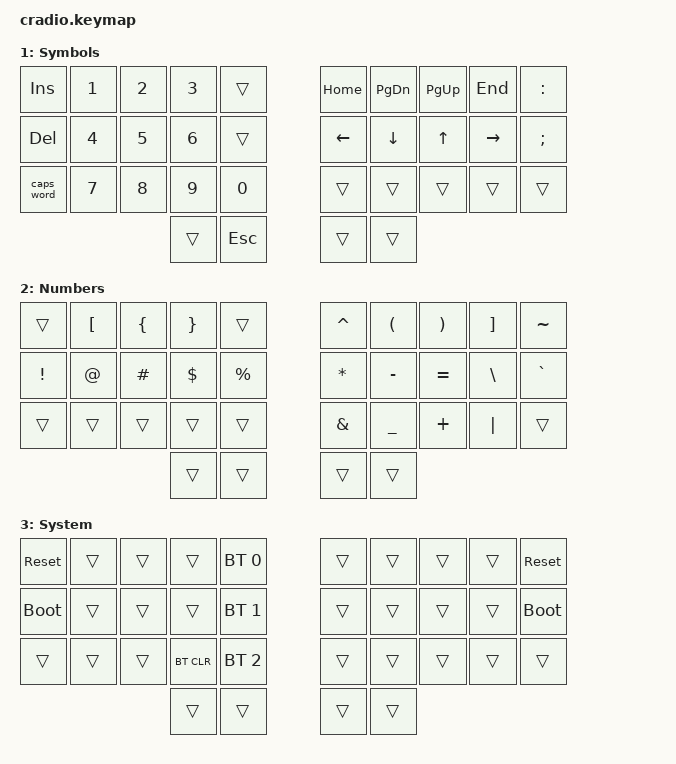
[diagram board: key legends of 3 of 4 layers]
// Copyright (c) 2022 The ZMK Contributors
// SPDX-License-Identifier: MIT

#include <behaviors.dtsi>
#include <dt-bindings/zmk/keys.h>
#include <dt-bindings/zmk/bt.h>

#define KEYS_L 0 1 2 3 4 10 11 12 13 14 20 21 22 23 24
#define KEYS_R 5 6 7 8 9 15 16 17 18 19 25 26 27 28 29

#define HRMR(k1,k2,k3,k4) \
    &hmr RGUI k1 \
    &hmr RCTRL k2 \
    &hmr RALT k3 \
    &hmr RSHFT k4

/ {
	behaviors {
		hml: left_homerow_mods {
			compatible = "zmk,behavior-hold-tap";
			#binding-cells = <2>;
			flavor = "balanced";
			tapping-term-ms = <150>; // <--- DECREASE THIS VALUE
			quick-tap-ms = <175>;
			bindings = <&kp>, <&kp>;
			hold-trigger-key-positions = <KEYS_R>;
			hold-trigger-on-release;
		};

		hmr: right_homerow_mods {
			compatible = "zmk,behavior-hold-tap";
			#binding-cells = <2>;
			flavor = "balanced";
			tapping-term-ms = <150>; // <--- DECREASE THIS VALUE
			quick-tap-ms = <175>;
			bindings = <&kp>, <&kp>;
			hold-trigger-key-positions = <KEYS_L>;
			hold-trigger-on-release;
		};

		lt_fast: layer_tap_fast {
			compatible = "zmk,behavior-hold-tap";
			#binding-cells = <2>;
			flavor = "hold-preferred";
			tapping-term-ms = <150>;
			quick-tap-ms = <0>;
			bindings = <&mo>, <&kp>;
		};

		td_z: tap_dance_z_esc_enter {
			compatible = "zmk,behavior-tap-dance";
			#binding-cells = <0>;
			tapping-term-ms = <200>;
			bindings = <&kp Z>, <&kp ESC>, <&kp ENTER>;
		};
	};

	keymap {
		compatible = "zmk,keymap";

	default_layer {
			display-name = "Default";
			bindings = <
        //╭──────────┬──────────┬──────────┬──────────┬──────────╮   ╭──────────┬──────────┬──────────┬──────────┬──────────╮
        //│  Q       │  W       │  E       │  R       │  T       │   │  Y       │  U       │  I       │  O       │  P       │
            &kp Q      &kp W      &kp E      &kp R      &kp T          &kp Y      &kp U      &kp I      &kp O      &kp P
        //├──────────┼──────────┼──────────┼──────────┼──────────┤   ├──────────┼──────────┼──────────┼──────────┼──────────┤
        //│  A       │  S       │  D       │  F       │  G       │   │  H       │  J       │  K       │  L       │ ' "      │
            &hml LSHFT A &kp S &kp D &hml LGUI F &kp G          &kp H      HRMR(J,     K,          L,          SEMI)
        //├──────────┼──────────┼──────────┼──────────┼──────────┤   ├──────────┼──────────┼──────────┼──────────┼──────────┤
        //│  Z       │  X       │  C       │  V       │  B       │   │  N       │  M       │ , <      │ . >      │ / ?      │
            &td_z      &kp X      &kp C      &kp V      &kp B          &kp N      &kp M      &kp COMMA  &kp DOT    &kp FSLH
        //╰──────────┴──────────┴──────────┼──────────┼──────────┤   ├──────────┼──────────┼──────────┴──────────┴──────────╯
                                            &lt_fast 2 TAB   &kp BSPC     &kp SPACE  &lt_fast 1 LS(ENTER)
        //                                 ╰──────────┴──────────╯   ╰──────────┴──────────╯
            >;
		};

right_layer {
			display-name = "Symbols";
			bindings = <
        //╭──────────┬──────────┬──────────┬──────────┬──────────╮   ╭──────────┬──────────┬──────────┬──────────┬──────────╮
        //│ INSERT   │  1       │  2       │  3       │          │   │ HOME     │ PAGE DN  │ PAGE UP  │ END      │  :       │
            &kp INS    &kp N1     &kp N2     &kp N3     &trans         &kp HOME   &kp PG_DN  &kp PG_UP  &kp END    &kp COLON
        //├──────────┼──────────┼──────────┼──────────┼──────────┤   ├──────────┼──────────┼──────────┼──────────┼──────────┤
        //│ DELETE   │  4       │  5       │  6       │          │   │ LEFT     │ DOWN     │ UP       │ RIGHT    │  ;       │
            &kp DEL    &kp N4     &kp N5     &kp N6     &trans         &kp LEFT   &kp DOWN   &kp UP   &kp RIGHT   &kp SEMI
        //├──────────┼──────────┼──────────┼──────────┼──────────┤   ├──────────┼──────────┼──────────┼──────────┼──────────┤
        //│ CAPS     │  7       │  8       │  9       │  0       │   │          │          │          │          │          │
           &caps_word  &kp N7     &kp N8     &kp N9     &kp N0         &trans     &trans     &trans     &trans     &trans
        //╰──────────┴──────────┴──────────┼──────────┼──────────┤   ├──────────┼──────────┼──────────┴──────────┴──────────╯
                                             &trans     &kp ESC        &trans     &trans
        //                                 ╰──────────┴──────────╯   ╰──────────┴──────────╯
            >;
		};

left_layer {
			display-name = "Numbers";
			bindings = <
        //╭──────────┬──────────┬──────────┬──────────┬──────────╮   ╭──────────┬──────────┬──────────┬──────────┬──────────╮
        //│          │  [       │  {       │  }       │          │   │  ^       │  (       │  )       │  ]       │  ~       │
            &trans     &kp LBKT   &kp LBRC   &kp RBRC   &trans         &kp CARET  &kp LPAR   &kp RPAR   &kp RBKT   &kp TILDE
        //├──────────┼──────────┼──────────┼──────────┼──────────┤   ├──────────┼──────────┼──────────┼──────────┼──────────┤
        //│  !       │  @       │  #       │  $       │  %       │   │  *       │  -       │  =       │  \       │  `       │
            &kp EXCL   &kp AT     &kp HASH   &kp DLLR   &kp PRCNT      &kp ASTRK  &kp MINUS  &kp EQUAL  &kp BSLH   &kp GRAVE
        //├──────────┼──────────┼──────────┼──────────┼──────────┤   ├──────────┼──────────┼──────────┼──────────┼──────────┤
        //│          │          │          │          │          │   │  &       │  _       │  +       │  │       │          │
            &trans     &trans     &trans     &trans     &trans         &kp AMPS   &kp UNDER  &kp PLUS   &kp PIPE   &trans
        //╰──────────┴──────────┴──────────┼──────────┼──────────┤   ├──────────┼──────────┼──────────┴──────────┴──────────╯
                                             &trans     &trans         &trans     &trans
        //                                 ╰──────────┴──────────╯   ╰──────────┴──────────╯
            >;
		};

tri_layer {
			display-name = "System";
			bindings = <
        //╭──────────┬──────────┬──────────┬──────────┬──────────╮   ╭──────────┬──────────┬──────────┬──────────┬──────────╮
        //│ RESET    │          │          │          │PROFILE 0 │   │          │          │          │          │  RESET   │
           &sys_reset  &trans     &trans     &trans    &bt BT_SEL 0    &trans     &trans     &trans     &trans    &sys_reset
        //├──────────┼──────────┼──────────┼──────────┼──────────┤   ├──────────┼──────────┼──────────┼──────────┼──────────┤
        //│BOOTLOADER│          │          │          │PROFILE 1 │   │          │          │          │          │BOOTLOADER│
          &bootloader  &trans     &trans     &trans    &bt BT_SEL 1    &trans     &trans     &trans     &trans    &bootloader
        //├──────────┼──────────┼──────────┼──────────┼──────────┤   ├──────────┼──────────┼──────────┼──────────┼──────────┤
        //│          │          │          │ CLEAR BT │PROFILE 2 │   │          │          │          │          │          │
            &trans     &trans     &trans    &bt BT_CLR &bt BT_SEL 2    &trans     &trans     &trans     &trans     &trans
        //╰──────────┴──────────┴──────────┼──────────┼──────────┤   ├──────────┼──────────┼──────────┴──────────┴──────────╯
                                             &trans     &trans         &trans     &trans
        //                                 ╰──────────┴──────────╯   ╰──────────┴──────────╯
            >;
		};
	};

	conditional_layers {
		compatible = "zmk,conditional-layers";

		tri_layer_logic {
			if-layers = <1 2>;
			then-layer = <3>;
		};
	};

	combos {
		compatible = "zmk,combos";

		combo_esc {
			timeout-ms = <50>;
			key-positions = <0 1>;
			bindings = <&kp ESC>;
		};
	};
};
